AUTOSAR XML (schema 00046)
package /HuaweiMDC/PlatformServices/McuSensorsAbstractApplication
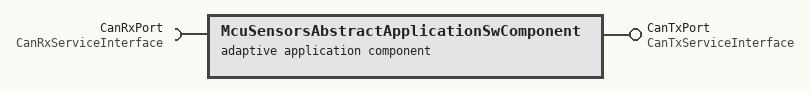
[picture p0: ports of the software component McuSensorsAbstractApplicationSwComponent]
  adaptive application sw component type McuSensorsAbstractApplicationSwComponent
    require port CanRxPort: required-interface=CanRxServiceInterface
    provide port CanTxPort: provided-interface=CanTxServiceInterface
package /HuaweiMDC/PlatformServices/McuSensorsAbstractExecutable
  executable McuSensorsAbstractExecutable
    root sw component prototype McuSensorsAbstractRootSwComponent: application-type=McuSensorsAbstractApplicationSwComponent
